AUTOSAR XML (schema 4.0)
package /ADAS_Components
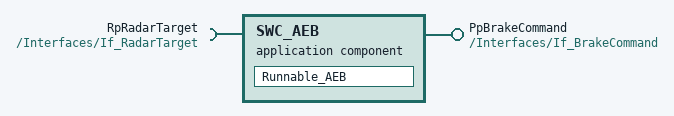
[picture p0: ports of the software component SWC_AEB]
  application sw component type SWC_AEB
    provide port PpBrakeCommand: provided-interface=/Interfaces/If_BrakeCommand
    require port RpRadarTarget: required-interface=/Interfaces/If_RadarTarget
    behavior IB_SWC_AEB
      runnable Runnable_AEB: symbol=C_Function_CalculateTTC
